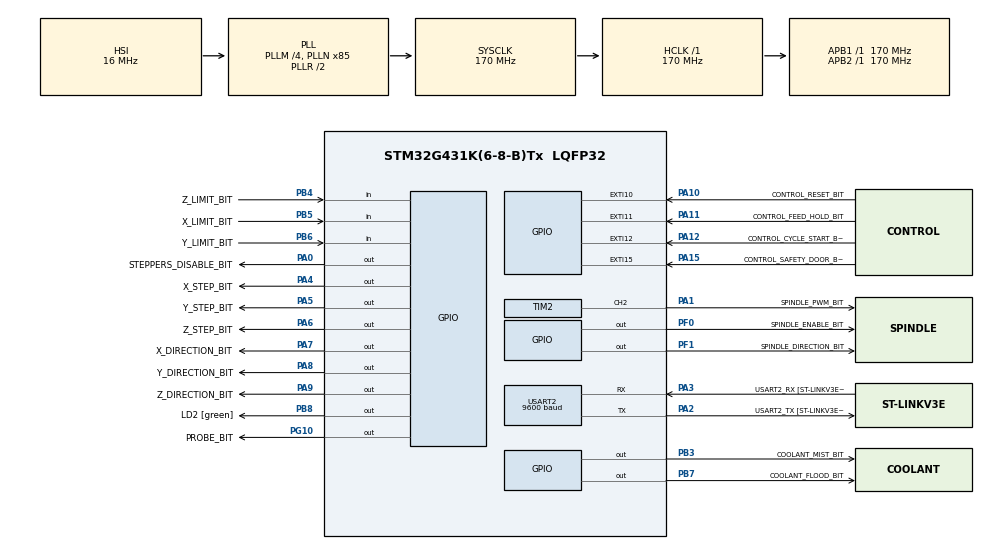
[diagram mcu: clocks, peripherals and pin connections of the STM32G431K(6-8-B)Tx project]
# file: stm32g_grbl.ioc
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Mcu.Family=STM32G4
Mcu.Name=STM32G431K(6-8-B)Tx
Mcu.Package=LQFP32
NVIC.EXTI15_10_IRQn=true\:0\:0\:false\:false\:true\:true\:true
NVIC.PriorityGroup=NVIC_PRIORITYGROUP_4
NVIC.TIM6_DAC_IRQn=true\:0\:0\:false\:false\:true\:true\:true
NVIC.TIM7_IRQn=true\:0\:0\:false\:false\:true\:true\:true
NVIC.USART2_IRQn=true\:0\:0\:false\:false\:true\:true\:true
PA0.GPIO_Label=STEPPERS_DISABLE_BIT
PA0.GPIO_Speed=GPIO_SPEED_FREQ_LOW
PA0.Signal=GPIO_Output
PA1.GPIO_Label=SPINDLE_PWM_BIT
PA1.Signal=S_TIM2_CH2
PA10.GPIO_Label=CONTROL_RESET_BIT
PA10.GPIO_ModeDefaultEXTI=GPIO_MODE_IT_FALLING
PA10.GPIO_PuPd=GPIO_PULLUP
PA10.Signal=GPXTI10
PA11.GPIO_Label=CONTROL_FEED_HOLD_BIT
PA11.GPIO_ModeDefaultEXTI=GPIO_MODE_IT_FALLING
PA11.GPIO_PuPd=GPIO_PULLUP
PA11.Signal=GPXTI11
PA12.GPIO_Label=CONTROL_CYCLE_START_BIT
PA12.GPIO_ModeDefaultEXTI=GPIO_MODE_IT_FALLING
PA12.GPIO_PuPd=GPIO_PULLUP
PA12.Signal=GPXTI12
PA13.GPIO_Label=T_SWDIO
PA13.Mode=Serial_Wire
PA13.Signal=SYS_JTMS-SWDIO
PA14.GPIO_Label=T_SWCLK
PA14.Mode=Serial_Wire
PA14.Signal=SYS_JTCK-SWCLK
PA15.GPIO_Label=CONTROL_SAFETY_DOOR_BIT
PA15.GPIO_ModeDefaultEXTI=GPIO_MODE_IT_FALLING
PA15.GPIO_PuPd=GPIO_PULLUP
PA15.Signal=GPXTI15
PA2.GPIO_Label=USART2_TX [ST-LINKV3E_VCP_RX]
PA2.Mode=Asynchronous
PA2.Signal=USART2_TX
PA3.GPIO_Label=USART2_RX [ST-LINKV3E_VCP_TX]
PA3.Mode=Asynchronous
PA3.Signal=USART2_RX
PA4.GPIO_Label=X_STEP_BIT
PA4.GPIO_Speed=GPIO_SPEED_FREQ_VERY_HIGH
PA4.Signal=GPIO_Output
PA5.GPIO_Label=Y_STEP_BIT
PA5.GPIO_Speed=GPIO_SPEED_FREQ_VERY_HIGH
PA5.Signal=GPIO_Output
PA6.GPIO_Label=Z_STEP_BIT
PA6.Signal=GPIO_Output
PA7.GPIO_Label=X_DIRECTION_BIT
PA7.Signal=GPIO_Output
PA8.GPIO_Label=Y_DIRECTION_BIT
PA8.Signal=GPIO_Output
PA9.GPIO_Label=Z_DIRECTION_BIT
PA9.Signal=GPIO_Output
PB3.GPIO_Label=COOLANT_MIST_BIT
PB3.Signal=GPIO_Output
PB4.GPIO_Label=Z_LIMIT_BIT
PB4.GPIO_PuPd=GPIO_PULLUP
PB4.Signal=GPIO_Input
PB5.GPIO_Label=X_LIMIT_BIT
PB5.GPIO_PuPd=GPIO_PULLUP
PB5.Signal=GPIO_Input
PB6.GPIO_Label=Y_LIMIT_BIT
PB6.GPIO_PuPd=GPIO_PULLUP
PB6.Signal=GPIO_Input
PB7.GPIO_Label=COOLANT_FLOOD_BIT
PB7.Signal=GPIO_Output
PB8-BOOT0.GPIO_Label=LD2 [green]
PB8-BOOT0.Signal=GPIO_Output
PF0-OSC_IN.GPIO_Label=SPINDLE_ENABLE_BIT
PF0-OSC_IN.Signal=GPIO_Output
PF1-OSC_OUT.GPIO_Label=SPINDLE_DIRECTION_BIT
PF1-OSC_OUT.Signal=GPIO_Output
PG10-NRST.GPIO_Label=PROBE_BIT
PG10-NRST.Signal=GPIO_Output
ProjectManager.HeapSize=0x200
ProjectManager.StackSize=0x400
ProjectManager.TargetToolchain=STM32CubeIDE
RCC.ADC12Freq_Value=170000000
RCC.AHBFreq_Value=170000000
RCC.APB1Freq_Value=170000000
RCC.APB1TimFreq_Value=170000000
RCC.APB2Freq_Value=170000000
RCC.APB2TimFreq_Value=170000000
RCC.CortexFreq_Value=170000000
RCC.EXTERNAL_CLOCK_VALUE=12288000
RCC.HCLKFreq_Value=170000000
RCC.HSE_VALUE=8000000
RCC.HSI48_VALUE=48000000
RCC.HSI_VALUE=16000000
RCC.LSE_VALUE=32768
RCC.PLLM=RCC_PLLM_DIV4
RCC.PLLN=85
RCC.SYSCLKFreq_VALUE=170000000
RCC.SYSCLKSource=RCC_SYSCLKSOURCE_PLLCLK
RCC.USBFreq_Value=170000000
RCC.VCOOutputFreq_Value=340000000
SH.S_TIM2_CH2.0=TIM2_CH2,PWM Generation2 CH2
TIM2.Channel-PWM\ Generation2\ CH2=TIM_CHANNEL_2
TIM6.AutoReloadPreload=TIM_AUTORELOAD_PRELOAD_ENABLE
TIM6.PeriodNoDither=30
TIM6.Prescaler=170
TIM7.PeriodNoDither=100
TIM7.Prescaler=170
USART2.BaudRate=9600
USART2.VirtualMode-Asynchronous=VM_ASYNC
USART2.WordLength=WORDLENGTH_8B
VP_SYS_VS_DBSignals.Mode=DisableDeadBatterySignals
VP_TIM2_VS_ClockSourceINT.Mode=Internal
VP_TIM6_VS_ClockSourceINT.Mode=Enable_Timer
VP_TIM6_VS_OPM.Mode=OPM_bit
VP_TIM7_VS_ClockSourceINT.Mode=Enable_Timer
VP_TIM7_VS_OPM.Mode=OPM_bit
board=NUCLEO-G431KB

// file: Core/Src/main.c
/* USER CODE BEGIN Header */
/**
  ******************************************************************************
  * @file           : main.c
  * @brief          : Main program body
  ******************************************************************************
  * @attention
  *
  * <h2><center>&copy; Copyright (c) 2020 STMicroelectronics.
  * All rights reserved.</center></h2>
  *
  * This software component is licensed by ST under BSD 3-Clause license,
  * the "License"; You may not use this file except in compliance with the
  * License. You may obtain a copy of the License at:
  *                        opensource.org/licenses/BSD-3-Clause
  *
  ******************************************************************************
  */
/* USER CODE END Header */

#include "main.h"

TIM_HandleTypeDef htim2;
TIM_HandleTypeDef htim6;
TIM_HandleTypeDef htim7;

UART_HandleTypeDef huart2;

void SystemClock_Config(void);
static void MX_GPIO_Init(void);
static void MX_USART2_UART_Init(void);
static void MX_TIM6_Init(void);
static void MX_TIM7_Init(void);
static void MX_TIM2_Init(void);

int main(void)
{

  /* MCU Configuration--------------------------------------------------------*/

  /* Reset of all peripherals, Initializes the Flash interface and the Systick. */
  HAL_Init();

  /* Configure the system clock */
  SystemClock_Config();

  /* Initialize all configured peripherals */
  MX_GPIO_Init();
  MX_USART2_UART_Init();
  MX_TIM6_Init();
  MX_TIM7_Init();
  MX_TIM2_Init();
  /* USER CODE BEGIN 2 */
  gerbil_loop();
  /* USER CODE END 2 */

  /* Infinite loop */
  while (1)
  {

  }
}

void SystemClock_Config(void)
{
  RCC_OscInitTypeDef RCC_OscInitStruct = {0};
  RCC_ClkInitTypeDef RCC_ClkInitStruct = {0};
  RCC_PeriphCLKInitTypeDef PeriphClkInit = {0};

  /** Configure the main internal regulator output voltage
  */
  HAL_PWREx_ControlVoltageScaling(PWR_REGULATOR_VOLTAGE_SCALE1_BOOST);
  /** Initializes the CPU, AHB and APB busses clocks
  */
  RCC_OscInitStruct.OscillatorType = RCC_OSCILLATORTYPE_HSI;
  RCC_OscInitStruct.HSIState = RCC_HSI_ON;
  RCC_OscInitStruct.HSICalibrationValue = RCC_HSICALIBRATION_DEFAULT;
  RCC_OscInitStruct.PLL.PLLState = RCC_PLL_ON;
  RCC_OscInitStruct.PLL.PLLSource = RCC_PLLSOURCE_HSI;
  RCC_OscInitStruct.PLL.PLLM = RCC_PLLM_DIV4;
  RCC_OscInitStruct.PLL.PLLN = 85;
  RCC_OscInitStruct.PLL.PLLP = RCC_PLLP_DIV2;
  RCC_OscInitStruct.PLL.PLLQ = RCC_PLLQ_DIV2;
  RCC_OscInitStruct.PLL.PLLR = RCC_PLLR_DIV2;
  if (HAL_RCC_OscConfig(&RCC_OscInitStruct) != HAL_OK)
  {
    Error_Handler();
  }
  /** Initializes the CPU, AHB and APB busses clocks
  */
  RCC_ClkInitStruct.ClockType = RCC_CLOCKTYPE_HCLK|RCC_CLOCKTYPE_SYSCLK
                              |RCC_CLOCKTYPE_PCLK1|RCC_CLOCKTYPE_PCLK2;
  RCC_ClkInitStruct.SYSCLKSource = RCC_SYSCLKSOURCE_PLLCLK;
  RCC_ClkInitStruct.AHBCLKDivider = RCC_SYSCLK_DIV1;
  RCC_ClkInitStruct.APB1CLKDivider = RCC_HCLK_DIV1;
  RCC_ClkInitStruct.APB2CLKDivider = RCC_HCLK_DIV1;

  if (HAL_RCC_ClockConfig(&RCC_ClkInitStruct, FLASH_LATENCY_8) != HAL_OK)
  {
    Error_Handler();
  }
  /** Initializes the peripherals clocks
  */
  PeriphClkInit.PeriphClockSelection = RCC_PERIPHCLK_USART2;
  PeriphClkInit.Usart2ClockSelection = RCC_USART2CLKSOURCE_PCLK1;
  if (HAL_RCCEx_PeriphCLKConfig(&PeriphClkInit) != HAL_OK)
  {
    Error_Handler();
  }
}

static void MX_TIM2_Init(void)
{

  TIM_ClockConfigTypeDef sClockSourceConfig = {0};
  TIM_MasterConfigTypeDef sMasterConfig = {0};
  TIM_OC_InitTypeDef sConfigOC = {0};

  htim2.Instance = TIM2;
  htim2.Init.Prescaler = 0;
  htim2.Init.CounterMode = TIM_COUNTERMODE_UP;
  htim2.Init.Period = 0;
  htim2.Init.ClockDivision = TIM_CLOCKDIVISION_DIV1;
  htim2.Init.AutoReloadPreload = TIM_AUTORELOAD_PRELOAD_DISABLE;
  if (HAL_TIM_Base_Init(&htim2) != HAL_OK)
  {
    Error_Handler();
  }
  sClockSourceConfig.ClockSource = TIM_CLOCKSOURCE_INTERNAL;
  if (HAL_TIM_ConfigClockSource(&htim2, &sClockSourceConfig) != HAL_OK)
  {
    Error_Handler();
  }
  if (HAL_TIM_PWM_Init(&htim2) != HAL_OK)
  {
    Error_Handler();
  }
  sMasterConfig.MasterOutputTrigger = TIM_TRGO_RESET;
  sMasterConfig.MasterSlaveMode = TIM_MASTERSLAVEMODE_DISABLE;
  if (HAL_TIMEx_MasterConfigSynchronization(&htim2, &sMasterConfig) != HAL_OK)
  {
    Error_Handler();
  }
  sConfigOC.OCMode = TIM_OCMODE_PWM1;
  sConfigOC.Pulse = 0;
  sConfigOC.OCPolarity = TIM_OCPOLARITY_HIGH;
  sConfigOC.OCFastMode = TIM_OCFAST_DISABLE;
  if (HAL_TIM_PWM_ConfigChannel(&htim2, &sConfigOC, TIM_CHANNEL_2) != HAL_OK)
  {
    Error_Handler();
  }
  HAL_TIM_MspPostInit(&htim2);

}

static void MX_TIM6_Init(void)
{

  TIM_MasterConfigTypeDef sMasterConfig = {0};

  htim6.Instance = TIM6;
  htim6.Init.Prescaler = 170;
  htim6.Init.CounterMode = TIM_COUNTERMODE_UP;
  htim6.Init.Period = 30;
  htim6.Init.AutoReloadPreload = TIM_AUTORELOAD_PRELOAD_ENABLE;
  if (HAL_TIM_Base_Init(&htim6) != HAL_OK)
  {
    Error_Handler();
  }
  if (HAL_TIM_OnePulse_Init(&htim6, TIM_OPMODE_SINGLE) != HAL_OK)
  {
    Error_Handler();
  }
  sMasterConfig.MasterOutputTrigger = TIM_TRGO_RESET;
  sMasterConfig.MasterSlaveMode = TIM_MASTERSLAVEMODE_DISABLE;
  if (HAL_TIMEx_MasterConfigSynchronization(&htim6, &sMasterConfig) != HAL_OK)
  {
    Error_Handler();
  }

}

static void MX_TIM7_Init(void)
{

  TIM_MasterConfigTypeDef sMasterConfig = {0};

  htim7.Instance = TIM7;
  htim7.Init.Prescaler = 170;
  htim7.Init.CounterMode = TIM_COUNTERMODE_UP;
  htim7.Init.Period = 100;
  htim7.Init.AutoReloadPreload = TIM_AUTORELOAD_PRELOAD_DISABLE;
  if (HAL_TIM_Base_Init(&htim7) != HAL_OK)
  {
    Error_Handler();
  }
  if (HAL_TIM_OnePulse_Init(&htim7, TIM_OPMODE_SINGLE) != HAL_OK)
  {
    Error_Handler();
  }
  sMasterConfig.MasterOutputTrigger = TIM_TRGO_RESET;
  sMasterConfig.MasterSlaveMode = TIM_MASTERSLAVEMODE_DISABLE;
  if (HAL_TIMEx_MasterConfigSynchronization(&htim7, &sMasterConfig) != HAL_OK)
  {
    Error_Handler();
  }

}

static void MX_USART2_UART_Init(void)
{

  huart2.Instance = USART2;
  huart2.Init.BaudRate = 9600;
  huart2.Init.WordLength = UART_WORDLENGTH_8B;
  huart2.Init.StopBits = UART_STOPBITS_1;
  huart2.Init.Parity = UART_PARITY_NONE;
  huart2.Init.Mode = UART_MODE_TX_RX;
  huart2.Init.HwFlowCtl = UART_HWCONTROL_NONE;
  huart2.Init.OverSampling = UART_OVERSAMPLING_16;
  huart2.Init.OneBitSampling = UART_ONE_BIT_SAMPLE_DISABLE;
  huart2.Init.ClockPrescaler = UART_PRESCALER_DIV1;
  huart2.AdvancedInit.AdvFeatureInit = UART_ADVFEATURE_NO_INIT;
  if (HAL_UART_Init(&huart2) != HAL_OK)
  {
    Error_Handler();
  }
  if (HAL_UARTEx_SetTxFifoThreshold(&huart2, UART_TXFIFO_THRESHOLD_1_8) != HAL_OK)
  {
    Error_Handler();
  }
  if (HAL_UARTEx_SetRxFifoThreshold(&huart2, UART_RXFIFO_THRESHOLD_1_8) != HAL_OK)
  {
    Error_Handler();
  }
  if (HAL_UARTEx_DisableFifoMode(&huart2) != HAL_OK)
  {
    Error_Handler();
  }

}

static void MX_GPIO_Init(void)
{
  GPIO_InitTypeDef GPIO_InitStruct = {0};

  /* GPIO Ports Clock Enable */
  __HAL_RCC_GPIOF_CLK_ENABLE();
  __HAL_RCC_GPIOG_CLK_ENABLE();
  __HAL_RCC_GPIOA_CLK_ENABLE();
  __HAL_RCC_GPIOB_CLK_ENABLE();

  /*Configure GPIO pin Output Level */
  HAL_GPIO_WritePin(GPIOF, SPINDLE_ENABLE_BIT_Pin|SPINDLE_DIRECTION_BIT_Pin, GPIO_PIN_RESET);

  /*Configure GPIO pin Output Level */
  HAL_GPIO_WritePin(PROBE_BIT_GPIO_Port, PROBE_BIT_Pin, GPIO_PIN_RESET);

  /*Configure GPIO pin Output Level */
  HAL_GPIO_WritePin(GPIOA, STEPPERS_DISABLE_BIT_Pin|X_STEP_BIT_Pin|Y_STEP_BIT_Pin|Z_STEP_BIT_Pin
                          |X_DIRECTION_BIT_Pin|Y_DIRECTION_BIT_Pin|Z_DIRECTION_BIT_Pin, GPIO_PIN_RESET);

  /*Configure GPIO pin Output Level */
  HAL_GPIO_WritePin(GPIOB, COOLANT_MIST_BIT_Pin|COOLANT_FLOOD_BIT_Pin|LD2_Pin, GPIO_PIN_RESET);

  /*Configure GPIO pins : SPINDLE_ENABLE_BIT_Pin SPINDLE_DIRECTION_BIT_Pin */
  GPIO_InitStruct.Pin = SPINDLE_ENABLE_BIT_Pin|SPINDLE_DIRECTION_BIT_Pin;
  GPIO_InitStruct.Mode = GPIO_MODE_OUTPUT_PP;
  GPIO_InitStruct.Pull = GPIO_NOPULL;
  GPIO_InitStruct.Speed = GPIO_SPEED_FREQ_LOW;
  HAL_GPIO_Init(GPIOF, &GPIO_InitStruct);

  /*Configure GPIO pin : PROBE_BIT_Pin */
  GPIO_InitStruct.Pin = PROBE_BIT_Pin;
  GPIO_InitStruct.Mode = GPIO_MODE_OUTPUT_PP;
  GPIO_InitStruct.Pull = GPIO_NOPULL;
  GPIO_InitStruct.Speed = GPIO_SPEED_FREQ_LOW;
  HAL_GPIO_Init(PROBE_BIT_GPIO_Port, &GPIO_InitStruct);

  /*Configure GPIO pins : STEPPERS_DISABLE_BIT_Pin Z_STEP_BIT_Pin X_DIRECTION_BIT_Pin Y_DIRECTION_BIT_Pin
                           Z_DIRECTION_BIT_Pin */
  GPIO_InitStruct.Pin = STEPPERS_DISABLE_BIT_Pin|Z_STEP_BIT_Pin|X_DIRECTION_BIT_Pin|Y_DIRECTION_BIT_Pin
                          |Z_DIRECTION_BIT_Pin;
  GPIO_InitStruct.Mode = GPIO_MODE_OUTPUT_PP;
  GPIO_InitStruct.Pull = GPIO_NOPULL;
  GPIO_InitStruct.Speed = GPIO_SPEED_FREQ_LOW;
  HAL_GPIO_Init(GPIOA, &GPIO_InitStruct);

  /*Configure GPIO pins : X_STEP_BIT_Pin Y_STEP_BIT_Pin */
  GPIO_InitStruct.Pin = X_STEP_BIT_Pin|Y_STEP_BIT_Pin;
  GPIO_InitStruct.Mode = GPIO_MODE_OUTPUT_PP;
  GPIO_InitStruct.Pull = GPIO_NOPULL;
  GPIO_InitStruct.Speed = GPIO_SPEED_FREQ_VERY_HIGH;
  HAL_GPIO_Init(GPIOA, &GPIO_InitStruct);

  /*Configure GPIO pins : CONTROL_RESET_BIT_Pin CONTROL_FEED_HOLD_BIT_Pin CONTROL_CYCLE_START_BIT_Pin CONTROL_SAFETY_DOOR_BIT_Pin */
  GPIO_InitStruct.Pin = CONTROL_RESET_BIT_Pin|CONTROL_FEED_HOLD_BIT_Pin|CONTROL_CYCLE_START_BIT_Pin|CONTROL_SAFETY_DOOR_BIT_Pin;
  GPIO_InitStruct.Mode = GPIO_MODE_IT_FALLING;
  GPIO_InitStruct.Pull = GPIO_PULLUP;
  HAL_GPIO_Init(GPIOA, &GPIO_InitStruct);

  /*Configure GPIO pins : COOLANT_MIST_BIT_Pin COOLANT_FLOOD_BIT_Pin LD2_Pin */
  GPIO_InitStruct.Pin = COOLANT_MIST_BIT_Pin|COOLANT_FLOOD_BIT_Pin|LD2_Pin;
  GPIO_InitStruct.Mode = GPIO_MODE_OUTPUT_PP;
  GPIO_InitStruct.Pull = GPIO_NOPULL;
  GPIO_InitStruct.Speed = GPIO_SPEED_FREQ_LOW;
  HAL_GPIO_Init(GPIOB, &GPIO_InitStruct);

  /*Configure GPIO pins : Z_LIMIT_BIT_Pin X_LIMIT_BIT_Pin Y_LIMIT_BIT_Pin */
  GPIO_InitStruct.Pin = Z_LIMIT_BIT_Pin|X_LIMIT_BIT_Pin|Y_LIMIT_BIT_Pin;
  GPIO_InitStruct.Mode = GPIO_MODE_INPUT;
  GPIO_InitStruct.Pull = GPIO_PULLUP;
  HAL_GPIO_Init(GPIOB, &GPIO_InitStruct);

  /* EXTI interrupt init*/
  HAL_NVIC_SetPriority(EXTI15_10_IRQn, 0, 0);
  HAL_NVIC_EnableIRQ(EXTI15_10_IRQn);

}

void Error_Handler(void)
{
}

/************************ (C) COPYRIGHT STMicroelectronics *****END OF FILE****/
